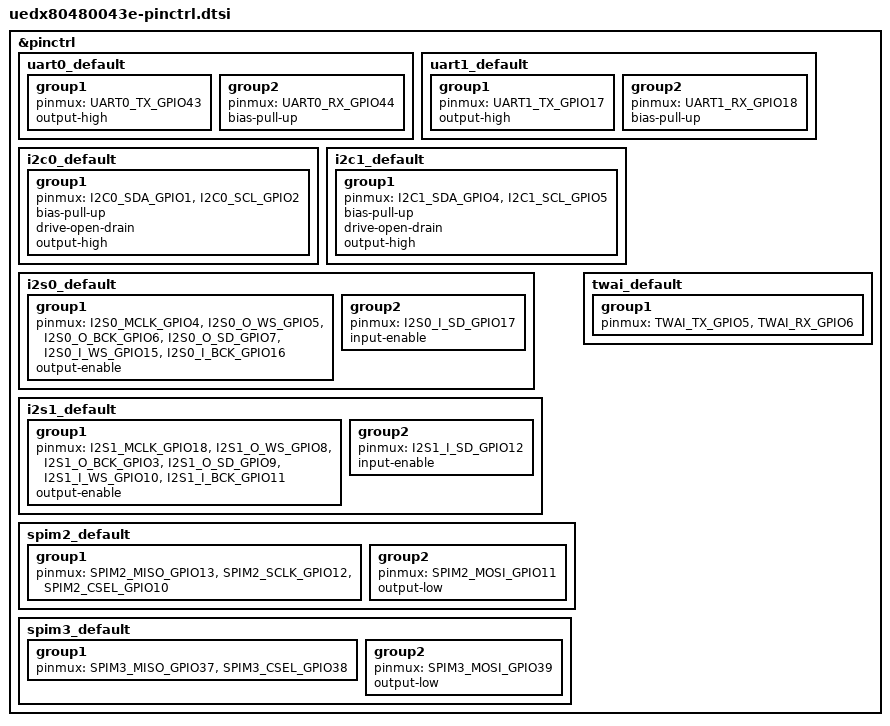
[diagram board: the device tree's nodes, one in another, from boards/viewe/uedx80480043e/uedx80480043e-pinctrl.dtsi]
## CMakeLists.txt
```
cmake_minimum_required(VERSION 3.20.0)
find_package(Zephyr REQUIRED HINTS $ENV{ZEPHYR_BASE})
project(volante_f1)
target_sources(app PRIVATE src/main.c)
```

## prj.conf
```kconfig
# Shell
CONFIG_SHELL=y
CONFIG_KERNEL_SHELL=y

CONFIG_CONSOLE=y
CONFIG_UART_CONSOLE=y
CONFIG_GPIO=y
CONFIG_LED=y
CONFIG_LOG=y
CONFIG_LOG_DEFAULT_LEVEL=3
CONFIG_PRINTK=y
CONFIG_SERIAL=y
CONFIG_UART_ESP32=y
CONFIG_UART_INTERRUPT_DRIVEN=y

# SPI Flash
CONFIG_FLASH=y
CONFIG_FLASH_MAP=y
CONFIG_ESPTOOLPY_OCT_FLASH=n
CONFIG_ESPTOOLPY_FLASHSIZE_16MB=y

# SPI RAM
CONFIG_ESP_SPIRAM=y
CONFIG_ESP_SPIRAM_MEMTEST=y
CONFIG_SPIRAM_MODE_OCT=y
CONFIG_SPIRAM_SPEED_40M=y
CONFIG_SPIRAM_FETCH_INSTRUCTIONS=y
CONFIG_SPIRAM_RODATA=y

# SPI Flash
CONFIG_ESPTOOLPY_FLASHFREQ_40M=y
CONFIG_ESPTOOLPY_FLASHMODE_DIO=y
```

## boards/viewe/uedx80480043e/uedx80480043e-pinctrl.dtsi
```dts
/*
 * Copyright (c) 2024 Espressif Systems (Shanghai) Co., Ltd.
 *
 * SPDX-License-Identifier: Apache-2.0
 */

#include <zephyr/dt-bindings/pinctrl/esp-pinctrl-common.h>
#include <dt-bindings/pinctrl/esp32s3-pinctrl.h>
#include <zephyr/dt-bindings/pinctrl/esp32s3-gpio-sigmap.h>

&pinctrl {
	uart0_default: uart0_default {
		group1 {
			pinmux = <UART0_TX_GPIO43>;
			output-high;
		};
		group2 {
			pinmux = <UART0_RX_GPIO44>;
			bias-pull-up;
		};
	};

	uart1_default: uart1_default {
		group1 {
			pinmux = <UART1_TX_GPIO17>;
			output-high;
		};
		group2 {
			pinmux = <UART1_RX_GPIO18>;
			bias-pull-up;
		};
	};

	i2c0_default: i2c0_default {
		group1 {
			pinmux = <I2C0_SDA_GPIO1>,
				 <I2C0_SCL_GPIO2>;
			bias-pull-up;
			drive-open-drain;
			output-high;
		};
	};

	i2c1_default: i2c1_default {
		group1 {
			pinmux = <I2C1_SDA_GPIO4>,
				 <I2C1_SCL_GPIO5>;
			bias-pull-up;
			drive-open-drain;
			output-high;
		};
	};

	i2s0_default: i2s0_default {
		group1 {
			pinmux = <I2S0_MCLK_GPIO4>,
				 <I2S0_O_WS_GPIO5>,
				 <I2S0_O_BCK_GPIO6>,
				 <I2S0_O_SD_GPIO7>,
				 <I2S0_I_WS_GPIO15>,
				 <I2S0_I_BCK_GPIO16>;
			output-enable;
		};
		group2 {
			pinmux = <I2S0_I_SD_GPIO17>;
			input-enable;
		};
	};

	i2s1_default: i2s1_default {
		group1 {
			pinmux = <I2S1_MCLK_GPIO18>,
				 <I2S1_O_WS_GPIO8>,
				 <I2S1_O_BCK_GPIO3>,
				 <I2S1_O_SD_GPIO9>,
				 <I2S1_I_WS_GPIO10>,
				 <I2S1_I_BCK_GPIO11>;
			output-enable;
		};
		group2 {
			pinmux = <I2S1_I_SD_GPIO12>;
			input-enable;
		};
	};

	spim2_default: spim2_default {
		group1 {
			pinmux = <SPIM2_MISO_GPIO13>,
				 <SPIM2_SCLK_GPIO12>,
				 <SPIM2_CSEL_GPIO10>;
		};
		group2 {
			pinmux = <SPIM2_MOSI_GPIO11>;
			output-low;
		};
	};

	spim3_default: spim3_default {
		group1 {
			pinmux = <SPIM3_MISO_GPIO37>,
				 //<SPIM3_SCLK_GPIO36>,
				 <SPIM3_CSEL_GPIO38>;
		};
		group2 {
			pinmux = <SPIM3_MOSI_GPIO39>;
			output-low;
		};
	};

	twai_default: twai_default {
		group1 {
			pinmux = <TWAI_TX_GPIO5>,
				<TWAI_RX_GPIO6>;
		};
	};
};
```

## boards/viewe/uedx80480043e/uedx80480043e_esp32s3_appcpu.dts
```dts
/dts-v1/;
#include <espressif/esp32s3/esp32s3_wroom_n16r8.dtsi>
#include <espressif/partitions_0x0_amp.dtsi>
/ {
    model = "UEDX80480043E Smart Display APPCPU";
    compatible = "espressif,esp32s3";

    chosen {
        zephyr,sram = &sram1;
		/* console can be UART or USB CDC */
		/* zephyr,console = &uart0; */
		/* zephyr,shell-uart = &uart0; */
		zephyr,console = &usb_serial;
		zephyr,shell-uart = &usb_serial;
		zephyr,flash = &flash0;
		zephyr,code-partition = &slot0_partition;
		zephyr,bt-hci = &esp32_bt_hci;
    };
};


&gpio0 {
	status = "okay";
};

&gpio1 {
	status = "okay";
};

&usb_serial {
	status = "okay";
};
```

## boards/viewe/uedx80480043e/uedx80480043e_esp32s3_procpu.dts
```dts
/dts-v1/;
#include <espressif/esp32s3/esp32s3_wroom_n16r8.dtsi>
#include "uedx80480043e-pinctrl.dtsi"
#include <zephyr/dt-bindings/input/input-event-codes.h>
#include <espressif/partitions_0x0_amp.dtsi>
#include <zephyr/dt-bindings/gpio/gpio.h>
#include <zephyr/dt-bindings/led/led.h>


/ {
    model = "UEDX80480043E Smart Display";
    compatible = "espressif,esp32s3";

    chosen {
        zephyr,sram = &sram1;
		/* console can be UART or USB CDC */
		/* zephyr,console = &uart0; */
		/* zephyr,shell-uart = &uart0; */
		zephyr,console = &usb_serial;
		zephyr,shell-uart = &usb_serial;
		zephyr,flash = &flash0;
		zephyr,code-partition = &slot0_partition;
		zephyr,bt-hci = &esp32_bt_hci;
    };

    aliases {
		led-strip = &led_strip;
	};

    led_strip: ws2812 {
		compatible = "worldsemi,ws2812-gpio";

		chain-length = <16>; /* arbitrary */
		color-mapping = <LED_COLOR_ID_GREEN
				 LED_COLOR_ID_RED
				 LED_COLOR_ID_BLUE>;
		/*
		 * Arduino D11 / P0.25, which was chosen to match the pin
		 * used in nrf52dk_nrf52832.overlay.
		 */
		gpios = <&gpio0 0 0>;
	};

	keypad {
        compatible = "gpio-keys";
        status = "okay";
        boot_button: button_boot {
            label = "BOOT Button";
            gpios = <&gpio0 0 (GPIO_PULL_UP | GPIO_ACTIVE_LOW)>;
            zephyr,code = <INPUT_KEY_MENU>;
        };
    };
};

&uart0 {
	status = "okay";
	current-speed = <115200>;
	pinctrl-0 = <&uart0_default>;
	pinctrl-names = "default";
};

&uart1 {
	status = "okay";
	current-speed = <115200>;
	pinctrl-0 = <&uart1_default>;
	pinctrl-names = "default";
};

&gpio0 {
	status = "okay";
};

&gpio1 {
	status = "okay";
};

&usb_serial {
	status = "okay";
};
```

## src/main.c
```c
/*
 * Copyright (c) 2012-2014 Wind River Systems, Inc.
 *
 * SPDX-License-Identifier: Apache-2.0
 */

#include <stdio.h>
#include <zephyr/kernel.h>
#include <zephyr/sys/printk.h>	

int main(void)
{	
while (1){
	printk("Hello World! %s\n", CONFIG_BOARD_TARGET);
	k_msleep(1000);
}
	return 0;
}
```
